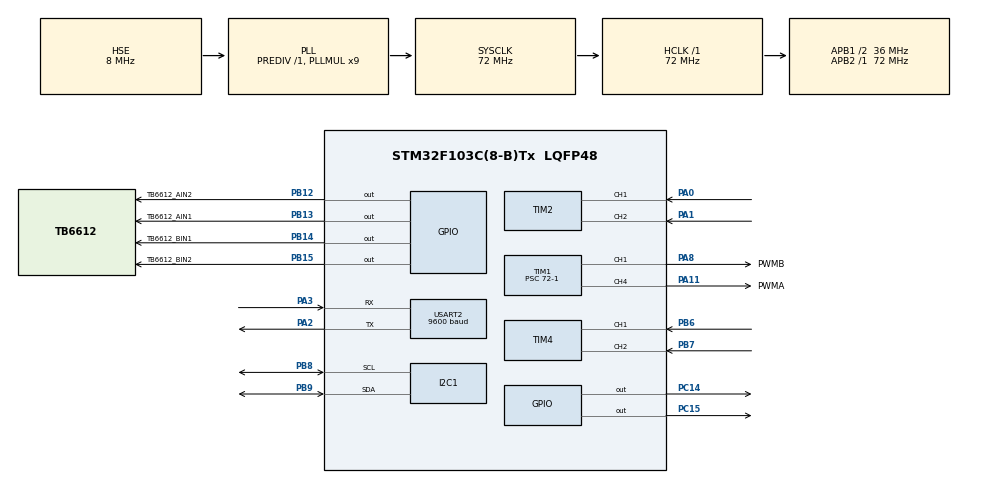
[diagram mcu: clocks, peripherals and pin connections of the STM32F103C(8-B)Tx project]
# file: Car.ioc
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Dma.Request0=USART2_RX
Dma.Request1=USART2_TX
Dma.USART2_RX.0.Direction=DMA_PERIPH_TO_MEMORY
Dma.USART2_RX.0.Instance=DMA1_Channel6
Dma.USART2_RX.0.MemDataAlignment=DMA_MDATAALIGN_BYTE
Dma.USART2_RX.0.MemInc=DMA_MINC_ENABLE
Dma.USART2_RX.0.Mode=DMA_NORMAL
Dma.USART2_RX.0.PeriphDataAlignment=DMA_PDATAALIGN_BYTE
Dma.USART2_RX.0.PeriphInc=DMA_PINC_DISABLE
Dma.USART2_RX.0.Priority=DMA_PRIORITY_LOW
Dma.USART2_TX.1.Direction=DMA_MEMORY_TO_PERIPH
Dma.USART2_TX.1.Instance=DMA1_Channel7
Dma.USART2_TX.1.MemDataAlignment=DMA_MDATAALIGN_BYTE
Dma.USART2_TX.1.MemInc=DMA_MINC_ENABLE
Dma.USART2_TX.1.Mode=DMA_NORMAL
Dma.USART2_TX.1.PeriphDataAlignment=DMA_PDATAALIGN_BYTE
Dma.USART2_TX.1.PeriphInc=DMA_PINC_DISABLE
Dma.USART2_TX.1.Priority=DMA_PRIORITY_LOW
FREERTOS.Queues01=YawQueue,1,YawData_t,0,Dynamic,NULL,NULL;ShowQueue,1,ShowData_t,0,Dynamic,NULL,NULL;BtCmdQueue,4,BtCmd_t,0,Dynamic,NULL,NULL
FREERTOS.Tasks01=MPUTask,40,384,StartMPUTask,As weak,NULL,Dynamic,NULL,NULL;MotorTask,24,512,StartMotorTask,As external,NULL,Dynamic,NULL,NULL;OLEDTask,8,512,StartOLEDTask,As external,NULL,Dynamic,NULL,NULL;BT24Task,16,256,StartBT24Task,As external,NULL,Dynamic,NULL,NULL;WatchDogTask,32,128,StartWatchDogTask,As external,NULL,Dynamic,NULL,NULL
FREERTOS.configTOTAL_HEAP_SIZE=8192
IWDG.Prescaler=IWDG_PRESCALER_32
Mcu.Family=STM32F1
Mcu.Name=STM32F103C(8-B)Tx
Mcu.Package=LQFP48
NVIC.DMA1_Channel6_IRQn=true\:5\:0\:false\:false\:true\:true\:false\:true\:true
NVIC.DMA1_Channel7_IRQn=true\:5\:0\:false\:false\:true\:true\:false\:true\:true
NVIC.PriorityGroup=NVIC_PRIORITYGROUP_4
NVIC.TIM3_IRQn=true\:15\:0\:false\:false\:true\:false\:false\:true\:true
NVIC.TimeBase=TIM3_IRQn
NVIC.TimeBaseIP=TIM3
NVIC.USART2_IRQn=true\:5\:0\:false\:false\:true\:true\:true\:true\:true
PA0-WKUP.Signal=S_TIM2_CH1_ETR
PA1.Signal=S_TIM2_CH2
PA11.GPIO_Label=PWMA
PA11.Signal=S_TIM1_CH4
PA13.Mode=Serial_Wire
PA13.Signal=SYS_JTMS-SWDIO
PA14.Mode=Serial_Wire
PA14.Signal=SYS_JTCK-SWCLK
PA2.Mode=Asynchronous
PA2.Signal=USART2_TX
PA3.Mode=Asynchronous
PA3.Signal=USART2_RX
PA8.GPIO_Label=PWMB
PA8.Signal=S_TIM1_CH1
PB12.GPIO_Label=TB6612_AIN2
PB12.Signal=GPIO_Output
PB13.GPIO_Label=TB6612_AIN1
PB13.Signal=GPIO_Output
PB14.GPIO_Label=TB6612_BIN1
PB14.Signal=GPIO_Output
PB15.GPIO_Label=TB6612_BIN2
PB15.Signal=GPIO_Output
PB6.Signal=S_TIM4_CH1
PB7.Signal=S_TIM4_CH2
PB8.Mode=I2C
PB8.Signal=I2C1_SCL
PB9.Mode=I2C
PB9.Signal=I2C1_SDA
PC14-OSC32_IN.GPIO_ModeDefaultOutputPP=GPIO_MODE_OUTPUT_OD
PC14-OSC32_IN.GPIO_PuPd=GPIO_PULLUP
PC14-OSC32_IN.GPIO_Speed=GPIO_SPEED_FREQ_HIGH
PC14-OSC32_IN.PinState=GPIO_PIN_SET
PC14-OSC32_IN.Signal=GPIO_Output
PC15-OSC32_OUT.GPIO_ModeDefaultOutputPP=GPIO_MODE_OUTPUT_OD
PC15-OSC32_OUT.GPIO_PuPd=GPIO_PULLUP
PC15-OSC32_OUT.GPIO_Speed=GPIO_SPEED_FREQ_HIGH
PC15-OSC32_OUT.PinState=GPIO_PIN_SET
PC15-OSC32_OUT.Signal=GPIO_Output
PD0-OSC_IN.Mode=HSE-External-Oscillator
PD0-OSC_IN.Signal=RCC_OSC_IN
PD1-OSC_OUT.Mode=HSE-External-Oscillator
PD1-OSC_OUT.Signal=RCC_OSC_OUT
ProjectManager.HeapSize=0x200
ProjectManager.StackSize=0x400
ProjectManager.TargetToolchain=CMake
RCC.AHBFreq_Value=72000000
RCC.APB1CLKDivider=RCC_HCLK_DIV2
RCC.APB1Freq_Value=36000000
RCC.APB1TimFreq_Value=72000000
RCC.APB2Freq_Value=72000000
RCC.APB2TimFreq_Value=72000000
RCC.HCLKFreq_Value=72000000
RCC.PLLMUL=RCC_PLL_MUL9
RCC.PLLSourceVirtual=RCC_PLLSOURCE_HSE
RCC.SYSCLKFreq_VALUE=72000000
RCC.SYSCLKSource=RCC_SYSCLKSOURCE_PLLCLK
RCC.USBFreq_Value=72000000
SH.S_TIM1_CH1.0=TIM1_CH1,PWM Generation1 CH1
SH.S_TIM1_CH4.0=TIM1_CH4,PWM Generation4 CH4
SH.S_TIM2_CH1_ETR.0=TIM2_CH1,Encoder_Interface
SH.S_TIM2_CH2.0=TIM2_CH2,Encoder_Interface
SH.S_TIM4_CH1.0=TIM4_CH1,Encoder_Interface
SH.S_TIM4_CH2.0=TIM4_CH2,Encoder_Interface
TIM1.Channel-PWM\ Generation1\ CH1=TIM_CHANNEL_1
TIM1.Channel-PWM\ Generation4\ CH4=TIM_CHANNEL_4
TIM1.Period=100-1
TIM1.Prescaler=72-1
TIM2.IC1Filter=15
TIM2.IC2Filter=15
TIM4.IC1Filter=15
TIM4.IC2Filter=15
USART2.BaudRate=9600
USART2.VirtualMode=VM_ASYNC
VP_FREERTOS_VS_CMSIS_V2.Mode=CMSIS_V2
VP_IWDG_VS_IWDG.Mode=IWDG_Activate
VP_SYS_VS_tim3.Mode=TIM3
VP_TIM1_VS_ClockSourceINT.Mode=Internal
board=custom

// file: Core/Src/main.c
/* USER CODE BEGIN Header */
/**
  ******************************************************************************
  * @file           : main.c
  * @brief          : Main program body
  ******************************************************************************
  * @attention
  *
  * Copyright (c) 2026 STMicroelectronics.
  * All rights reserved.
  *
  * This software is licensed under terms that can be found in the LICENSE file
  * in the root directory of this software component.
  * If no LICENSE file comes with this software, it is provided AS-IS.
  *
  ******************************************************************************
  */
/* USER CODE END Header */
#include "main.h"
#include "cmsis_os.h"
#include "dma.h"
#include "i2c.h"
#include "iwdg.h"
#include "tim.h"
#include "usart.h"
#include "gpio.h"

/* USER CODE BEGIN Includes */
#include <tb6612.h>
/* USER CODE END Includes */

void SystemClock_Config(void);
void MX_FREERTOS_Init(void);

int main(void)
{

  /* MCU Configuration--------------------------------------------------------*/

  /* Reset of all peripherals, Initializes the Flash interface and the Systick. */
  HAL_Init();

  /* Configure the system clock */
  SystemClock_Config();

  /* Initialize all configured peripherals */
  MX_GPIO_Init();
  MX_DMA_Init();
  MX_TIM1_Init();
  MX_TIM2_Init();
  MX_TIM4_Init();
  MX_I2C1_Init();
  MX_USART2_UART_Init();
  MX_IWDG_Init();

  /* Init scheduler */
  osKernelInitialize();  /* Call init function for freertos objects (in cmsis_os2.c) */
  MX_FREERTOS_Init();

  /* Start scheduler */
  osKernelStart();

  /* We should never get here as control is now taken by the scheduler */

  /* Infinite loop */
  while (1)
  {

  }
}

void SystemClock_Config(void)
{
  RCC_OscInitTypeDef RCC_OscInitStruct = {0};
  RCC_ClkInitTypeDef RCC_ClkInitStruct = {0};

  /** Initializes the RCC Oscillators according to the specified parameters
  * in the RCC_OscInitTypeDef structure.
  */
  RCC_OscInitStruct.OscillatorType = RCC_OSCILLATORTYPE_LSI|RCC_OSCILLATORTYPE_HSE;
  RCC_OscInitStruct.HSEState = RCC_HSE_ON;
  RCC_OscInitStruct.HSEPredivValue = RCC_HSE_PREDIV_DIV1;
  RCC_OscInitStruct.HSIState = RCC_HSI_ON;
  RCC_OscInitStruct.LSIState = RCC_LSI_ON;
  RCC_OscInitStruct.PLL.PLLState = RCC_PLL_ON;
  RCC_OscInitStruct.PLL.PLLSource = RCC_PLLSOURCE_HSE;
  RCC_OscInitStruct.PLL.PLLMUL = RCC_PLL_MUL9;
  if (HAL_RCC_OscConfig(&RCC_OscInitStruct) != HAL_OK)
  {
    Error_Handler();
  }

  /** Initializes the CPU, AHB and APB buses clocks
  */
  RCC_ClkInitStruct.ClockType = RCC_CLOCKTYPE_HCLK|RCC_CLOCKTYPE_SYSCLK
                              |RCC_CLOCKTYPE_PCLK1|RCC_CLOCKTYPE_PCLK2;
  RCC_ClkInitStruct.SYSCLKSource = RCC_SYSCLKSOURCE_PLLCLK;
  RCC_ClkInitStruct.AHBCLKDivider = RCC_SYSCLK_DIV1;
  RCC_ClkInitStruct.APB1CLKDivider = RCC_HCLK_DIV2;
  RCC_ClkInitStruct.APB2CLKDivider = RCC_HCLK_DIV1;

  if (HAL_RCC_ClockConfig(&RCC_ClkInitStruct, FLASH_LATENCY_2) != HAL_OK)
  {
    Error_Handler();
  }
}

void HAL_TIM_PeriodElapsedCallback(TIM_HandleTypeDef *htim)
{
  if (htim->Instance == TIM3)
  {
    HAL_IncTick();
  }
}

void Error_Handler(void)
{
  __disable_irq();
  while (1)
  {
  }
}

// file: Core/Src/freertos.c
/* USER CODE BEGIN Header */
/**
  ******************************************************************************
  * File Name          : freertos.c
  * Description        : Code for freertos applications
  ******************************************************************************
  * @attention
  *
  * Copyright (c) 2026 STMicroelectronics.
  * All rights reserved.
  *
  * This software is licensed under terms that can be found in the LICENSE file
  * in the root directory of this software component.
  * If no LICENSE file comes with this software, it is provided AS-IS.
  *
  ******************************************************************************
  */
/* USER CODE END Header */

#include "FreeRTOS.h"
#include "task.h"
#include "main.h"
#include "cmsis_os.h"

/* USER CODE BEGIN Includes */
#include "telemetry.h"

/* USER CODE END Includes */

/* Definitions for MPUTask */
osThreadId_t MPUTaskHandle;
const osThreadAttr_t MPUTask_attributes = {
  .name = "MPUTask",
  .stack_size = 384 * 4,
  .priority = (osPriority_t) osPriorityHigh,
};
/* Definitions for MotorTask */
osThreadId_t MotorTaskHandle;
const osThreadAttr_t MotorTask_attributes = {
  .name = "MotorTask",
  .stack_size = 512 * 4,
  .priority = (osPriority_t) osPriorityNormal,
};
/* Definitions for OLEDTask */
osThreadId_t OLEDTaskHandle;
const osThreadAttr_t OLEDTask_attributes = {
  .name = "OLEDTask",
  .stack_size = 512 * 4,
  .priority = (osPriority_t) osPriorityLow,
};
/* Definitions for BT24Task */
osThreadId_t BT24TaskHandle;
const osThreadAttr_t BT24Task_attributes = {
  .name = "BT24Task",
  .stack_size = 256 * 4,
  .priority = (osPriority_t) osPriorityBelowNormal,
};
/* Definitions for WatchDogTask */
osThreadId_t WatchDogTaskHandle;
const osThreadAttr_t WatchDogTask_attributes = {
  .name = "WatchDogTask",
  .stack_size = 128 * 4,
  .priority = (osPriority_t) osPriorityAboveNormal,
};
/* Definitions for YawQueue */
osMessageQueueId_t YawQueueHandle;
const osMessageQueueAttr_t YawQueue_attributes = {
  .name = "YawQueue"
};
/* Definitions for ShowQueue */
osMessageQueueId_t ShowQueueHandle;
const osMessageQueueAttr_t ShowQueue_attributes = {
  .name = "ShowQueue"
};
/* Definitions for BtCmdQueue */
osMessageQueueId_t BtCmdQueueHandle;
const osMessageQueueAttr_t BtCmdQueue_attributes = {
  .name = "BtCmdQueue"
};

void StartMPUTask(void *argument);
extern void StartMotorTask(void *argument);
extern void StartOLEDTask(void *argument);
extern void StartBT24Task(void *argument);
extern void StartWatchDogTask(void *argument);

void MX_FREERTOS_Init(void); /* (MISRA C 2004 rule 8.1) */

void MX_FREERTOS_Init(void) {

  /* Create the queue(s) */
  /* creation of YawQueue */
  YawQueueHandle = osMessageQueueNew (1, sizeof(YawData_t), &YawQueue_attributes);

  /* creation of ShowQueue */
  ShowQueueHandle = osMessageQueueNew (1, sizeof(ShowData_t), &ShowQueue_attributes);

  /* creation of BtCmdQueue */
  BtCmdQueueHandle = osMessageQueueNew (4, sizeof(BtCmd_t), &BtCmdQueue_attributes);

  /* Create the thread(s) */
  /* creation of MPUTask */
  MPUTaskHandle = osThreadNew(StartMPUTask, NULL, &MPUTask_attributes);

  /* creation of MotorTask */
  MotorTaskHandle = osThreadNew(StartMotorTask, NULL, &MotorTask_attributes);

  /* creation of OLEDTask */
  OLEDTaskHandle = osThreadNew(StartOLEDTask, NULL, &OLEDTask_attributes);

  /* creation of BT24Task */
  BT24TaskHandle = osThreadNew(StartBT24Task, NULL, &BT24Task_attributes);

  /* creation of WatchDogTask */
  WatchDogTaskHandle = osThreadNew(StartWatchDogTask, NULL, &WatchDogTask_attributes);

}

__weak void StartMPUTask(void *argument)
{
  for(;;)
  {
    osDelay(1);
  }
}
